VERSION ""

NS_ :

BS_:

BU_: XXX

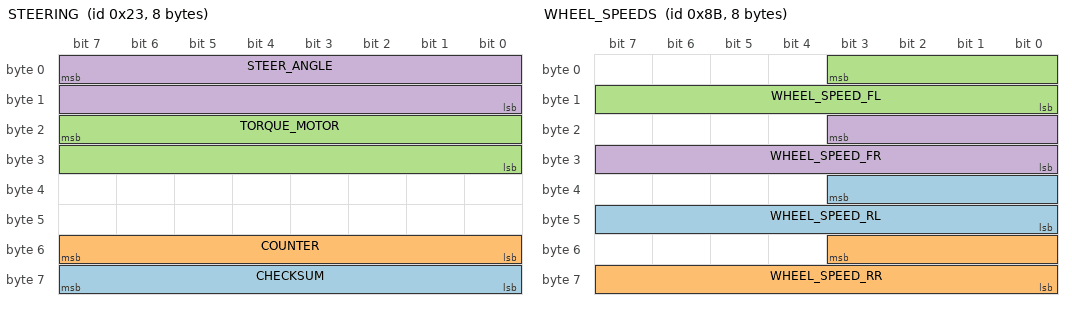
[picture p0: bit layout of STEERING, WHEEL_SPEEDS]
BO_ 35 STEERING: 8 XXX
 SG_ CHECKSUM : 63|8@0+ (1,0) [0|65535] "" XXX
 SG_ COUNTER : 55|8@0+ (1,0) [0|1] "" XXX
 SG_ TORQUE_MOTOR : 23|16@0+ (1,-4096) [0|65535] "" XXX
 SG_ STEER_ANGLE : 7|16@0+ (0.4,-1643) [0|65535] "degs" XXX

BO_ 139 WHEEL_SPEEDS: 8 XXX
 SG_ WHEEL_SPEED_RL : 35|12@0+ (1,0) [0|1] "" XXX
 SG_ WHEEL_SPEED_RR : 51|12@0+ (1,0) [0|1] "" XXX
 SG_ WHEEL_SPEED_FL : 3|12@0+ (1,0) [0|1] "" XXX
 SG_ WHEEL_SPEED_FR : 19|12@0+ (1,0) [0|1] "" XXX

BO_ 166 FORWARD_CAMERA: 8 XXX
 SG_ LKAS_COMMAND : 15|16@0+ (1,-1024) [0|4095] "" XXX
 SG_ LKAS_STATE : 25|1@0+ (1,0) [0|1] "" XXX

BO_ 311 SEATBELT_DRIVER_UNLATCHED: 8 XXX
 SG_ SEATBELT_DRIVER_UNLATCHED : 60|5@0+ (1,0) [0|31] "" XXX

BO_ 792 STEERING_LEVER: 8 XXX
 SG_ TURN_SIGNALS : 0|2@1+ (1,0) [0|3] "" XXX
 SG_ HIGH_BEAM_FLASH : 2|2@1+ (1,0) [0|3] "" XXX

BO_ 133 PRNDL: 8 XXX
 SG_ PRNDL : 5|14@0+ (1,0) [0|16383] "" XXX

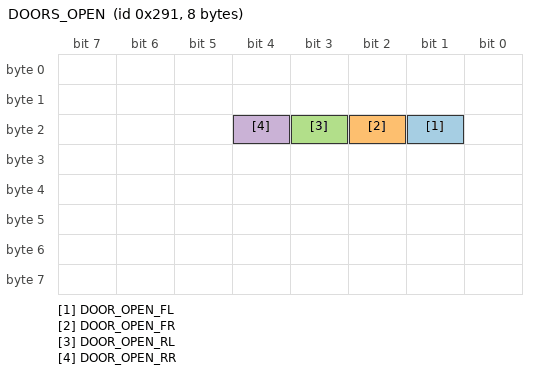
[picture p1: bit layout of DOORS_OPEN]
BO_ 657 DOORS_OPEN: 8 XXX
 SG_ DOOR_OPEN_FL : 17|1@0+ (1,0) [0|1] "" XXX
 SG_ DOOR_OPEN_FR : 18|1@1+ (1,0) [0|3] "" XXX
 SG_ DOOR_OPEN_RL : 19|1@0+ (1,0) [0|1] "" XXX
 SG_ DOOR_OPEN_RR : 20|1@0+ (1,0) [0|1] "" XXX

BO_ 47 BRAKE_PEDAL: 8 XXX
 SG_ BRAKE_PRESSED : 32|2@1+ (1,0) [0|3] "" XXX

BO_ 37 GAS_PEDAL: 8 XXX
 SG_ ACCL_134 : 36|13@0+ (1,0) [0|8191] "" XXX

BO_ 129 ACC_STATUS: 8 XXX
 SG_ ACC_STATUS_2 : 5|1@0+ (1,0) [0|1] "" XXX

BO_ 296 STEER_RATE: 8 XXX
 SG_ STEER_RATE : 23|8@0+ (1,0) [0|255] "" XXX

CM_ SG_ 35 STEER_ANGLE "negative values indicate right turn, positive values indicate left turn";
CM_ SG_ 166 LKAS_STATE "appears to be the lkas ready indicator";
CM_ SG_ 792 TURN_SIGNALS "RIGHT IS 2 LEFT IS 1";
CM_ SG_ 792 HIGH_BEAM_FLASH "4 IS EMABLE, 8 IS FLASH HIGH BEAMS";
